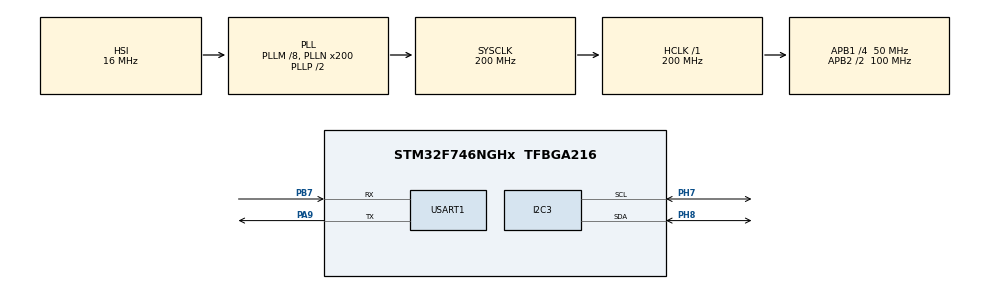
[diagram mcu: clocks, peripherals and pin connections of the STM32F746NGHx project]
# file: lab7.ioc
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I2C3.Timing=0x00C0EAFF
Mcu.Family=STM32F7
Mcu.Name=STM32F746NGHx
Mcu.Package=TFBGA216
NVIC.PriorityGroup=NVIC_PRIORITYGROUP_4
PA9.Mode=Asynchronous
PA9.Signal=USART1_TX
PB7.Mode=Asynchronous
PB7.Signal=USART1_RX
PH7.GPIO_Pu=GPIO_PULLUP
PH7.Mode=I2C
PH7.Signal=I2C3_SCL
PH8.GPIO_Pu=GPIO_PULLUP
PH8.Mode=I2C
PH8.Signal=I2C3_SDA
ProjectManager.HeapSize=0x200
ProjectManager.StackSize=0x400
ProjectManager.TargetToolchain=STM32CubeIDE
RCC.AHBFreq_Value=200000000
RCC.APB1CLKDivider=RCC_HCLK_DIV4
RCC.APB1Freq_Value=50000000
RCC.APB1TimFreq_Value=100000000
RCC.APB2CLKDivider=RCC_HCLK_DIV2
RCC.APB2Freq_Value=100000000
RCC.APB2TimFreq_Value=200000000
RCC.CortexFreq_Value=200000000
RCC.HCLKFreq_Value=200000000
RCC.HSE_VALUE=25000000
RCC.HSI_VALUE=16000000
RCC.PLL48CLockSelection=RCC_CLK48SOURCE_PLLSAIP
RCC.PLLI2SN=100
RCC.PLLM=8
RCC.PLLN=200
RCC.PLLQ=9
RCC.PLLSAIN=384
RCC.PLLSAIP=RCC_PLLSAIP_DIV8
RCC.PLLSAIR=5
RCC.PLLSAIRDiv=RCC_PLLSAIDIVR_8
RCC.SDMMCClockSelection=RCC_SDMMC1CLKSOURCE_CLK48
RCC.SYSCLKFreq_VALUE=200000000
RCC.SYSCLKSource=RCC_SYSCLKSOURCE_PLLCLK
RCC.USBFreq_Value=96000000
RCC.VCOOutputFreq_Value=400000000
USART1.VirtualMode-Asynchronous=VM_ASYNC
board=STM32F746G-DISCO

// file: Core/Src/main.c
/* USER CODE BEGIN Header */
/**
 ******************************************************************************
 * @file           : main.c
 * @brief          : Main program body
 ******************************************************************************
 * @attention
 *
 * <h2><center>&copy; Copyright (c) 2023 STMicroelectronics.
 * All rights reserved.</center></h2>
 *
 * This software component is licensed by ST under Ultimate Liberty license
 * SLA0044, the "License"; You may not use this file except in compliance with
 * the License. You may obtain a copy of the License at:
 *                             www.st.com/SLA0044
 *
 ******************************************************************************
 */
/* USER CODE END Header */
#include "main.h"

I2C_HandleTypeDef hi2c3;

UART_HandleTypeDef huart1;

void SystemClock_Config(void);
static void MX_GPIO_Init(void);
static void MX_USART1_UART_Init(void);
static void MX_I2C3_Init(void);

int main(void)
{

  /* MCU Configuration--------------------------------------------------------*/

  /* Reset of all peripherals, Initializes the Flash interface and the Systick. */
  HAL_Init();

  /* Configure the system clock */
  SystemClock_Config();

  /* Initialize all configured peripherals */
  MX_GPIO_Init();
  MX_USART1_UART_Init();
  MX_I2C3_Init();
  /* USER CODE BEGIN 2 */
  uint8_t addressRead = 0b00110101;
  uint8_t addressWrite = 0b00110100;

  /* USER CODE END 2 */

  /* Infinite loop */
	while (1)
	{

    /* USER CODE BEGIN 3 */

		HAL_UART_Transmit(&huart1, "test\r\n", strlen("test\r\n"), HAL_MAX_DELAY);

		HAL_I2C_Master_Transmit(&hi2c3, addressWrite, pData, Size, HAL_MAX_DELAY);
	}
  /* USER CODE END 3 */
}

void SystemClock_Config(void)
{
  RCC_OscInitTypeDef RCC_OscInitStruct = {0};
  RCC_ClkInitTypeDef RCC_ClkInitStruct = {0};
  RCC_PeriphCLKInitTypeDef PeriphClkInitStruct = {0};

  /** Configure the main internal regulator output voltage
  */
  __HAL_RCC_PWR_CLK_ENABLE();
  __HAL_PWR_VOLTAGESCALING_CONFIG(PWR_REGULATOR_VOLTAGE_SCALE1);
  /** Initializes the RCC Oscillators according to the specified parameters
  * in the RCC_OscInitTypeDef structure.
  */
  RCC_OscInitStruct.OscillatorType = RCC_OSCILLATORTYPE_HSI;
  RCC_OscInitStruct.HSIState = RCC_HSI_ON;
  RCC_OscInitStruct.HSICalibrationValue = RCC_HSICALIBRATION_DEFAULT;
  RCC_OscInitStruct.PLL.PLLState = RCC_PLL_ON;
  RCC_OscInitStruct.PLL.PLLSource = RCC_PLLSOURCE_HSI;
  RCC_OscInitStruct.PLL.PLLM = 8;
  RCC_OscInitStruct.PLL.PLLN = 200;
  RCC_OscInitStruct.PLL.PLLP = RCC_PLLP_DIV2;
  RCC_OscInitStruct.PLL.PLLQ = 9;
  if (HAL_RCC_OscConfig(&RCC_OscInitStruct) != HAL_OK)
  {
    Error_Handler();
  }
  /** Activate the Over-Drive mode
  */
  if (HAL_PWREx_EnableOverDrive() != HAL_OK)
  {
    Error_Handler();
  }
  /** Initializes the CPU, AHB and APB buses clocks
  */
  RCC_ClkInitStruct.ClockType = RCC_CLOCKTYPE_HCLK|RCC_CLOCKTYPE_SYSCLK
                              |RCC_CLOCKTYPE_PCLK1|RCC_CLOCKTYPE_PCLK2;
  RCC_ClkInitStruct.SYSCLKSource = RCC_SYSCLKSOURCE_PLLCLK;
  RCC_ClkInitStruct.AHBCLKDivider = RCC_SYSCLK_DIV1;
  RCC_ClkInitStruct.APB1CLKDivider = RCC_HCLK_DIV4;
  RCC_ClkInitStruct.APB2CLKDivider = RCC_HCLK_DIV2;

  if (HAL_RCC_ClockConfig(&RCC_ClkInitStruct, FLASH_LATENCY_6) != HAL_OK)
  {
    Error_Handler();
  }
  PeriphClkInitStruct.PeriphClockSelection = RCC_PERIPHCLK_USART1|RCC_PERIPHCLK_I2C3;
  PeriphClkInitStruct.Usart1ClockSelection = RCC_USART1CLKSOURCE_PCLK2;
  PeriphClkInitStruct.I2c3ClockSelection = RCC_I2C3CLKSOURCE_PCLK1;
  if (HAL_RCCEx_PeriphCLKConfig(&PeriphClkInitStruct) != HAL_OK)
  {
    Error_Handler();
  }
}

static void MX_I2C3_Init(void)
{

  hi2c3.Instance = I2C3;
  hi2c3.Init.Timing = 0x00C0EAFF;
  hi2c3.Init.OwnAddress1 = 0;
  hi2c3.Init.AddressingMode = I2C_ADDRESSINGMODE_7BIT;
  hi2c3.Init.DualAddressMode = I2C_DUALADDRESS_DISABLE;
  hi2c3.Init.OwnAddress2 = 0;
  hi2c3.Init.OwnAddress2Masks = I2C_OA2_NOMASK;
  hi2c3.Init.GeneralCallMode = I2C_GENERALCALL_DISABLE;
  hi2c3.Init.NoStretchMode = I2C_NOSTRETCH_DISABLE;
  if (HAL_I2C_Init(&hi2c3) != HAL_OK)
  {
    Error_Handler();
  }
  /** Configure Analogue filter
  */
  if (HAL_I2CEx_ConfigAnalogFilter(&hi2c3, I2C_ANALOGFILTER_ENABLE) != HAL_OK)
  {
    Error_Handler();
  }
  /** Configure Digital filter
  */
  if (HAL_I2CEx_ConfigDigitalFilter(&hi2c3, 0) != HAL_OK)
  {
    Error_Handler();
  }

}

static void MX_USART1_UART_Init(void)
{

  huart1.Instance = USART1;
  huart1.Init.BaudRate = 115200;
  huart1.Init.WordLength = UART_WORDLENGTH_8B;
  huart1.Init.StopBits = UART_STOPBITS_1;
  huart1.Init.Parity = UART_PARITY_NONE;
  huart1.Init.Mode = UART_MODE_TX_RX;
  huart1.Init.HwFlowCtl = UART_HWCONTROL_NONE;
  huart1.Init.OverSampling = UART_OVERSAMPLING_16;
  huart1.Init.OneBitSampling = UART_ONE_BIT_SAMPLE_DISABLE;
  huart1.AdvancedInit.AdvFeatureInit = UART_ADVFEATURE_NO_INIT;
  if (HAL_UART_Init(&huart1) != HAL_OK)
  {
    Error_Handler();
  }

}

static void MX_GPIO_Init(void)
{

  /* GPIO Ports Clock Enable */
  __HAL_RCC_GPIOB_CLK_ENABLE();
  __HAL_RCC_GPIOA_CLK_ENABLE();
  __HAL_RCC_GPIOH_CLK_ENABLE();

}

void Error_Handler(void)
{
	__disable_irq();
	while (1)
	{
	}
}

/************************ (C) COPYRIGHT STMicroelectronics *****END OF FILE****/
